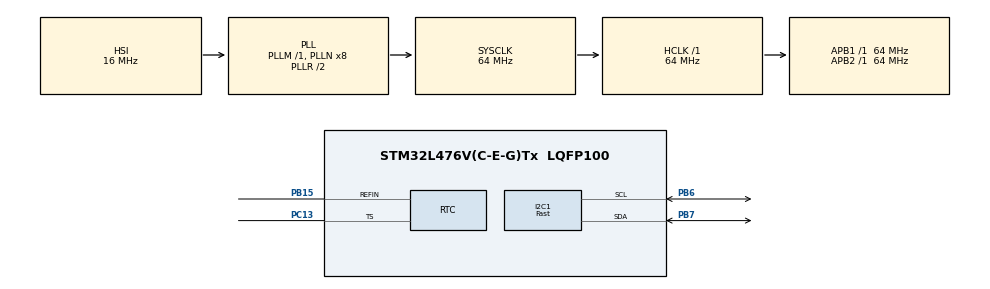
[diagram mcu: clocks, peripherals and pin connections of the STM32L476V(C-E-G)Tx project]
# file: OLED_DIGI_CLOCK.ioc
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I2C1.CustomTiming=Disabled
I2C1.I2C_Speed_Mode=I2C_Fast
I2C1.Timing=0x00602173
Mcu.Family=STM32L4
Mcu.Name=STM32L476V(C-E-G)Tx
Mcu.Package=LQFP100
NVIC.I2C1_EV_IRQn=true\:0\:0\:false\:false\:true\:true\:true\:true
NVIC.PriorityGroup=NVIC_PRIORITYGROUP_4
PB15.Mode=Reference_Clock_Detection_Activate
PB15.Signal=RTC_REFIN
PB6.Mode=I2C
PB6.Signal=I2C1_SCL
PB7.Mode=I2C
PB7.Signal=I2C1_SDA
PC13.Mode=Timestamp enabled
PC13.Signal=RTC_TS
ProjectManager.HeapSize=0x200
ProjectManager.StackSize=0x400
ProjectManager.TargetToolchain=STM32CubeIDE
RCC.ADCFreq_Value=64000000
RCC.AHBFreq_Value=64000000
RCC.APB1Freq_Value=64000000
RCC.APB1TimFreq_Value=64000000
RCC.APB2Freq_Value=64000000
RCC.APB2TimFreq_Value=64000000
RCC.CortexFreq_Value=64000000
RCC.HCLKFreq_Value=64000000
RCC.HSE_VALUE=8000000
RCC.HSI_VALUE=16000000
RCC.LSE_VALUE=32768
RCC.MSI_VALUE=4000000
RCC.PLLSourceVirtual=RCC_PLLSOURCE_HSI
RCC.PREFETCH_ENABLE=1
RCC.SYSCLKFreq_VALUE=64000000
RCC.SYSCLKSource=RCC_SYSCLKSOURCE_PLLCLK
RCC.USBFreq_Value=64000000
RCC.VCOOutputFreq_Value=128000000
RTC.Date=20
RTC.HourFormat=RTC_HOURFORMAT_12
RTC.Hours=2
RTC.Minutes=37
RTC.Month=RTC_MONTH_JULY
RTC.WeekDay=RTC_WEEKDAY_WEDNESDAY
RTC.Year=22
VP_RTC_VS_RTC_Activate.Mode=RTC_Enabled
VP_RTC_VS_RTC_Calendar.Mode=RTC_Calendar
board=STM32L476G-DISCO

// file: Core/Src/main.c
/* USER CODE BEGIN Header */
/**
  ******************************************************************************
  * @file           : main.c
  * @brief          : Main program body
  ******************************************************************************
  * @attention
  *
  * Copyright (c) 2022 STMicroelectronics.
  * All rights reserved.
  *
  * This software is licensed under terms that can be found in the LICENSE file
  * in the root directory of this software component.
  * If no LICENSE file comes with this software, it is provided AS-IS.
  *
  ******************************************************************************
  */
/* USER CODE END Header */
#include "main.h"
//#include "ssd1306.h"

#include "fonts.h"
#include "ssd1306.h"
#include "test.h"
#include "bitmap.h"
#include "horse_anim.h"
#include "stdlib.h"
//#include "ssd1306_tests.h"

/* USER CODE BEGIN PM */
uint8_t aShowTime[50] = {0};
uint8_t aShowDate[50] = {0};
/* USER CODE END PM */

I2C_HandleTypeDef hi2c1;

RTC_HandleTypeDef hrtc;
void OLED_init();

/* USER CODE BEGIN PV */
void OLED_init()
{
   // ssd1306_TestAll();
}

void loop() {
	HAL_Delay(100);
}
/* USER CODE BEGIN PV */
uint8_t new_day,new_date,new_month,new_year,new_hrs,new_mins,new_secs=0;

/* Private user code ---------------------------------------------------------*/
/* USER CODE BEGIN 0 */
RTC_TimeTypeDef currTime = {0};
RTC_DateTypeDef currDate = {0};

/* USER CODE END PV */

void SystemClock_Config(void);
static void MX_GPIO_Init(void);
static void MX_I2C1_Init(void);
static void MX_RTC_Init(void);

static void RTC_CalendarUpdate(uint8_t *showtime, uint8_t *showdate);
/* USER CODE BEGIN PFP */
void display_time (void);
/* USER CODE END PFP */

int main(void)
{

  /* MCU Configuration--------------------------------------------------------*/

  /* Reset of all peripherals, Initializes the Flash interface and the Systick. */
  HAL_Init();

  /* Configure the system clock */
  SystemClock_Config();

  /* Initialize all configured peripherals */
  MX_GPIO_Init();
  MX_I2C1_Init();
  MX_RTC_Init();
  SSD1306_Init();  // initialise

    /// lets print some string

      SSD1306_GotoXY (0,0);
      SSD1306_Puts ("HELLO", &Font_11x18, 1);
      SSD1306_GotoXY (10, 30);
      SSD1306_Puts ("  WORLD :)", &Font_11x18, 1);
      SSD1306_UpdateScreen(); //display

      HAL_Delay (2000);

      SSD1306_ScrollRight(0,7);  // scroll entire screen
      HAL_Delay(2000);  // 2 sec

      SSD1306_ScrollLeft(0,7);  // scroll entire screen
      HAL_Delay(2000);  // 2 sec

      SSD1306_Stopscroll();
      SSD1306_Clear();

      SSD1306_DrawBitmap(0,0,logo, 128, 64, 1);
      SSD1306_UpdateScreen();

      HAL_Delay(2000);

      SSD1306_ScrollRight(0x00, 0x0f);    // scroll entire screen right

      HAL_Delay (2000);

      SSD1306_ScrollLeft(0x00, 0x0f);  // scroll entire screen left

      HAL_Delay (2000);

      SSD1306_Scrolldiagright(0x00, 0x0f);  // scroll entire screen diagonal right

      HAL_Delay (2000);
      SSD1306_Scrolldiagleft(0x00, 0x0f);  // scroll entire screen diagonal left

      HAL_Delay (2000);

      SSD1306_Stopscroll();   // stop scrolling. If not done, screen will keep on scrolling

      SSD1306_InvertDisplay(1);   // invert the display

      HAL_Delay(1000);

      SSD1306_InvertDisplay(0);  // normalize the display
      SSD1306_Clear();

      HAL_Delay(1000);

      OLED_init();
     // HAL_RTC_GetTime(&hrtc);

   /* Infinite loop */
   /* USER CODE BEGIN WHILE */
   while (1)
   {

 		SSD1306_Clear();
 			  SSD1306_DrawBitmap(0,0,horse1,128,64,1);
 			  SSD1306_UpdateScreen();

 			  SSD1306_Clear();
 			  SSD1306_DrawBitmap(0,0,horse2,128,64,1);
 			  SSD1306_UpdateScreen();

 			  SSD1306_Clear();
 			  SSD1306_DrawBitmap(0,0,horse3,128,64,1);
 			  SSD1306_UpdateScreen();

 			  SSD1306_Clear();
 			  SSD1306_DrawBitmap(0,0,horse4,128,64,1);
 			  SSD1306_UpdateScreen();

 			  SSD1306_Clear();
 			  SSD1306_DrawBitmap(0,0,horse5,128,64,1);
 			  SSD1306_UpdateScreen();

 			  SSD1306_Clear();
 			  SSD1306_DrawBitmap(0,0,horse6,128,64,1);
 			  SSD1306_UpdateScreen();

 			  SSD1306_Clear();
 			  SSD1306_DrawBitmap(0,0,horse7,128,64,1);
 			  SSD1306_UpdateScreen();

 			  SSD1306_Clear();
 			  SSD1306_DrawBitmap(0,0,horse8,128,64,1);
 			  SSD1306_UpdateScreen();

 			  SSD1306_Clear();
 			  SSD1306_DrawBitmap(0,0,horse9,128,64,1);
 			  SSD1306_UpdateScreen();

 			  SSD1306_Clear();
 			  SSD1306_DrawBitmap(0,0,horse10,128,64,1);
 			  SSD1306_UpdateScreen();

 			// display_time();
 			// HAL_Delay(1000);

   }

   /* USER CODE END 3 */
 }
/**
  * @brief  Display the current time and date.
  * @param  showtime : pointer to buffer
  * @param  showdate : pointer to buffer
  * @retval None
  */
static void RTC_CalendarUpdate(uint8_t *showtime, uint8_t *showdate)
{

  RTC_DateTypeDef sdatestructureget;
  RTC_TimeTypeDef stimestructureget;

  /* Get the RTC current Time */
  if (HAL_RTC_GetTime(&hrtc, &stimestructureget, RTC_FORMAT_BIN) != HAL_OK)
  {
    /* HAL Error */
    Error_Handler();
  }

  /* Get the RTC current Date */
  if (HAL_RTC_GetDate(&hrtc, &sdatestructureget, RTC_FORMAT_BIN) != HAL_OK)
  {
    /* HAL Error */
    Error_Handler();
  }

  /* Display time Format : hh:mm:ss */
  sprintf((char *)showtime, "%02d:%02d:%02d", stimestructureget.Hours, stimestructureget.Minutes, stimestructureget.Seconds);
  /* Display date Format : mm-dd-yy */
  sprintf((char *)showdate, "%02d-%02d-%02d", sdatestructureget.Date, sdatestructureget.Month, 2000 + sdatestructureget.Year);
}

void display_time (void)
{
	 RTC_CalendarUpdate(aShowTime, aShowDate);
	 SSD1306_Fill(0);
	 SSD1306_GotoXY(2, 2);
	  SSD1306_Puts("DIGI-CLOCK", &Font_11x18, 1);
	  SSD1306_GotoXY(20, 25);
	  SSD1306_Puts(aShowTime, &Font_11x18, 1);
	  SSD1306_GotoXY(15, 45);
	  SSD1306_Puts(aShowDate, &Font_11x18, 1);
	  SSD1306_UpdateScreen();

}
void SystemClock_Config(void)
{
  RCC_OscInitTypeDef RCC_OscInitStruct = {0};
  RCC_ClkInitTypeDef RCC_ClkInitStruct = {0};

  /** Configure the main internal regulator output voltage
  */
  if (HAL_PWREx_ControlVoltageScaling(PWR_REGULATOR_VOLTAGE_SCALE1) != HAL_OK)
  {
    Error_Handler();
  }

  /** Initializes the RCC Oscillators according to the specified parameters
  * in the RCC_OscInitTypeDef structure.
  */
  RCC_OscInitStruct.OscillatorType = RCC_OSCILLATORTYPE_HSI|RCC_OSCILLATORTYPE_LSI;
  RCC_OscInitStruct.HSIState = RCC_HSI_ON;
  RCC_OscInitStruct.HSICalibrationValue = RCC_HSICALIBRATION_DEFAULT;
  RCC_OscInitStruct.LSIState = RCC_LSI_ON;
  RCC_OscInitStruct.PLL.PLLState = RCC_PLL_ON;
  RCC_OscInitStruct.PLL.PLLSource = RCC_PLLSOURCE_HSI;
  RCC_OscInitStruct.PLL.PLLM = 1;
  RCC_OscInitStruct.PLL.PLLN = 8;
  RCC_OscInitStruct.PLL.PLLP = RCC_PLLP_DIV7;
  RCC_OscInitStruct.PLL.PLLQ = RCC_PLLQ_DIV2;
  RCC_OscInitStruct.PLL.PLLR = RCC_PLLR_DIV2;
  if (HAL_RCC_OscConfig(&RCC_OscInitStruct) != HAL_OK)
  {
    Error_Handler();
  }

  /** Initializes the CPU, AHB and APB buses clocks
  */
  RCC_ClkInitStruct.ClockType = RCC_CLOCKTYPE_HCLK|RCC_CLOCKTYPE_SYSCLK
                              |RCC_CLOCKTYPE_PCLK1|RCC_CLOCKTYPE_PCLK2;
  RCC_ClkInitStruct.SYSCLKSource = RCC_SYSCLKSOURCE_PLLCLK;
  RCC_ClkInitStruct.AHBCLKDivider = RCC_SYSCLK_DIV1;
  RCC_ClkInitStruct.APB1CLKDivider = RCC_HCLK_DIV1;
  RCC_ClkInitStruct.APB2CLKDivider = RCC_HCLK_DIV1;

  if (HAL_RCC_ClockConfig(&RCC_ClkInitStruct, FLASH_LATENCY_3) != HAL_OK)
  {
    Error_Handler();
  }
}

static void MX_I2C1_Init(void)
{

  hi2c1.Instance = I2C1;
  hi2c1.Init.Timing = 0x00602173;
  hi2c1.Init.OwnAddress1 = 0;
  hi2c1.Init.AddressingMode = I2C_ADDRESSINGMODE_7BIT;
  hi2c1.Init.DualAddressMode = I2C_DUALADDRESS_DISABLE;
  hi2c1.Init.OwnAddress2 = 0;
  hi2c1.Init.OwnAddress2Masks = I2C_OA2_NOMASK;
  hi2c1.Init.GeneralCallMode = I2C_GENERALCALL_DISABLE;
  hi2c1.Init.NoStretchMode = I2C_NOSTRETCH_DISABLE;
  if (HAL_I2C_Init(&hi2c1) != HAL_OK)
  {
    Error_Handler();
  }

  /** Configure Analogue filter
  */
  if (HAL_I2CEx_ConfigAnalogFilter(&hi2c1, I2C_ANALOGFILTER_ENABLE) != HAL_OK)
  {
    Error_Handler();
  }

  /** Configure Digital filter
  */
  if (HAL_I2CEx_ConfigDigitalFilter(&hi2c1, 0) != HAL_OK)
  {
    Error_Handler();
  }

}

static void MX_RTC_Init(void)
{

  RTC_TimeTypeDef sTime = {0};
  RTC_DateTypeDef sDate = {0};

  /** Initialize RTC Only
  */
  hrtc.Instance = RTC;
  hrtc.Init.HourFormat = RTC_HOURFORMAT_12;
  hrtc.Init.AsynchPrediv = 127;
  hrtc.Init.SynchPrediv = 255;
  hrtc.Init.OutPut = RTC_OUTPUT_DISABLE;
  hrtc.Init.OutPutRemap = RTC_OUTPUT_REMAP_NONE;
  hrtc.Init.OutPutPolarity = RTC_OUTPUT_POLARITY_HIGH;
  hrtc.Init.OutPutType = RTC_OUTPUT_TYPE_OPENDRAIN;
  if (HAL_RTC_Init(&hrtc) != HAL_OK)
  {
    Error_Handler();
  }

  /** Initialize RTC and set the Time and Date
  */
  sTime.Hours = 0x4;
  sTime.Minutes = 0x14;
  sTime.Seconds = 0x0;
  sTime.TimeFormat = RTC_HOURFORMAT12_AM;
  sTime.DayLightSaving = RTC_DAYLIGHTSAVING_NONE;
  sTime.StoreOperation = RTC_STOREOPERATION_RESET;
  if (HAL_RTC_SetTime(&hrtc, &sTime, RTC_FORMAT_BCD) != HAL_OK)
  {
    Error_Handler();
  }
  sDate.WeekDay = RTC_WEEKDAY_WEDNESDAY;
  sDate.Month = RTC_MONTH_JULY;
  sDate.Date = 0x10;
  sDate.Year = 0x22;

  if (HAL_RTC_SetDate(&hrtc, &sDate, RTC_FORMAT_BCD) != HAL_OK)
  {
    Error_Handler();
  }

  /** Enable the TimeStamp
  */
  if (HAL_RTCEx_SetTimeStamp(&hrtc, RTC_TIMESTAMPEDGE_RISING, RTC_TIMESTAMPPIN_DEFAULT) != HAL_OK)
  {
    Error_Handler();
  }

  /** Enable the reference Clock input
  */
  if (HAL_RTCEx_SetRefClock(&hrtc) != HAL_OK)
  {
    Error_Handler();
  }

}

static void MX_GPIO_Init(void)
{

  /* GPIO Ports Clock Enable */
  __HAL_RCC_GPIOC_CLK_ENABLE();
  __HAL_RCC_GPIOB_CLK_ENABLE();

}

void Error_Handler(void)
{
  __disable_irq();
  while (1)
  {
  }
}
